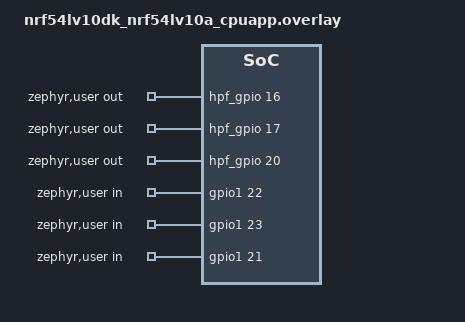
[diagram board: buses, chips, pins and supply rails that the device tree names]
/*
 * Copyright (c) 2026 Nordic Semiconductor ASA
 *
 * SPDX-License-Identifier: LicenseRef-Nordic-5-Clause
 */

/* Test requires GPIO loopback:
 * - between P1.16 and P1.22,
 * - between P1.17 and P1.23,
 * - between P1.20 and P1.21.
 */

/ {
	/* Test requirements:
	 * out-gpios[0] wire connected with in-gpios[0],
	 * out-gpios[1] wire connected with in-gpios[1],
	 * etc.
	 * Output-input GPIO pair must have identical active level flag.
	 * All outputs must be on the same device.
	 */
	zephyr,user {
		out-gpios = <&hpf_gpio 16 GPIO_ACTIVE_HIGH>, <&hpf_gpio 17 GPIO_ACTIVE_HIGH>,
			    <&hpf_gpio 20 GPIO_ACTIVE_HIGH>;

		in-gpios = <&gpio1 22 GPIO_ACTIVE_HIGH>, <&gpio1 23 GPIO_ACTIVE_HIGH>,
			   <&gpio1 21 GPIO_ACTIVE_HIGH>;
	};
};

&gpiote20 {
	status = "okay";
};

&gpio1 {
	status = "okay";
};
